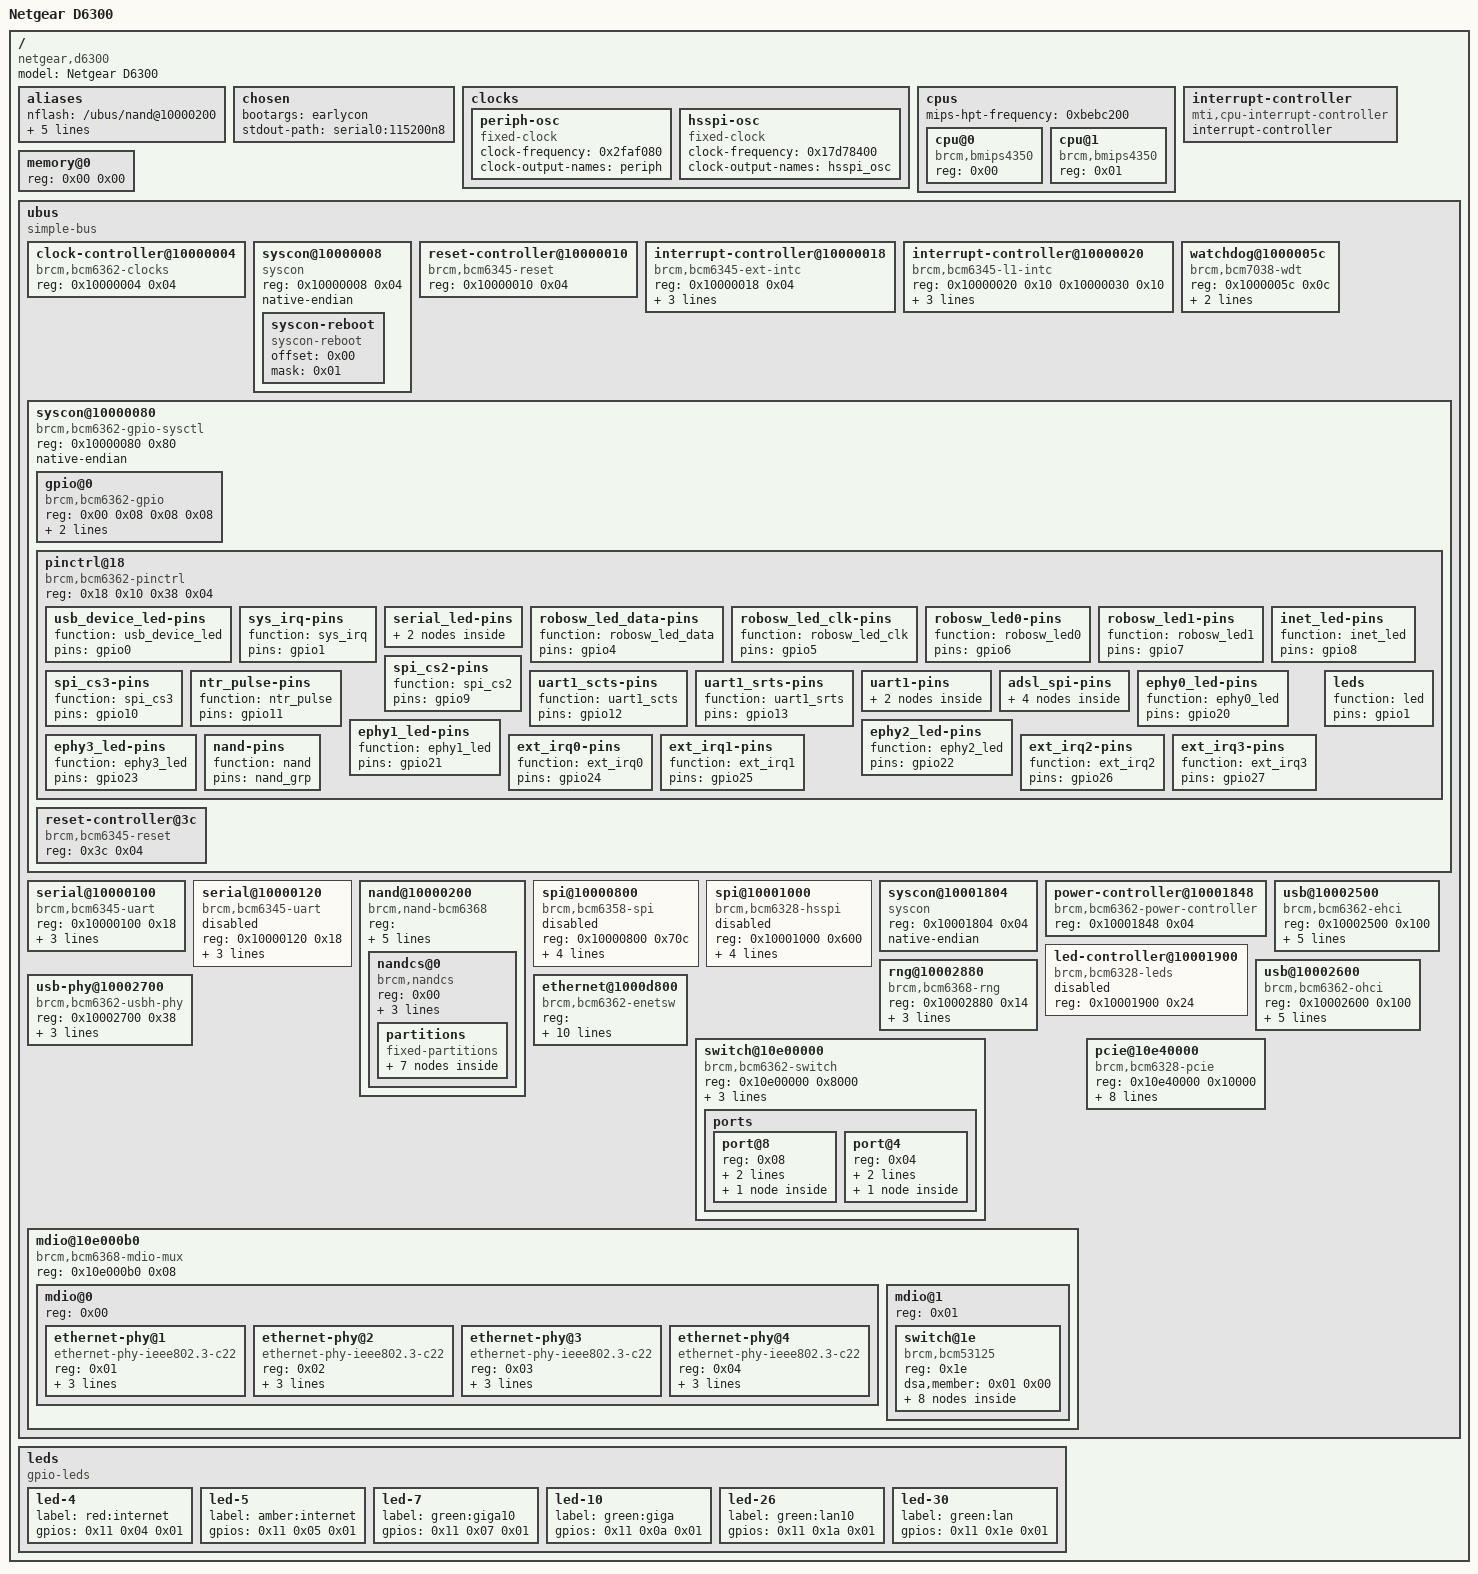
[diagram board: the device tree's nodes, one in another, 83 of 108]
/dts-v1/;

/ {
	#address-cells = <0x01>;
	#size-cells = <0x01>;
	compatible = "netgear,d6300", "brcm,bcm6362";
	model = "Netgear D6300";

	aliases {
		nflash = "/ubus/nand@10000200";
		pinctrl = "/ubus/syscon@10000080/pinctrl@18";
		serial0 = "/ubus/serial@10000100";
		serial1 = "/ubus/serial@10000120";
		spi0 = "/ubus/spi@10000800";
		spi1 = "/ubus/spi@10001000";
	};

	chosen {
		bootargs = "earlycon";
		stdout-path = "serial0:115200n8";
	};

	clocks {

		periph-osc {
			compatible = "fixed-clock";
			#clock-cells = <0x00>;
			clock-frequency = <0x2faf080>;
			clock-output-names = "periph";
			phandle = <0x03>;
		};

		hsspi-osc {
			compatible = "fixed-clock";
			#clock-cells = <0x00>;
			clock-frequency = <0x17d78400>;
			clock-output-names = "hsspi_osc";
			phandle = <0x08>;
		};
	};

	cpus {
		#address-cells = <0x01>;
		#size-cells = <0x00>;
		mips-hpt-frequency = <0xbebc200>;

		cpu@0 {
			compatible = "brcm,bmips4350", "mips,mips4Kc";
			device_type = "cpu";
			reg = <0x00>;
		};

		cpu@1 {
			compatible = "brcm,bmips4350", "mips,mips4Kc";
			device_type = "cpu";
			reg = <0x01>;
		};
	};

	interrupt-controller {
		#address-cells = <0x00>;
		compatible = "mti,cpu-interrupt-controller";
		interrupt-controller;
		#interrupt-cells = <0x01>;
		phandle = <0x02>;
	};

	memory@0 {
		device_type = "memory";
		reg = <0x00 0x00>;
	};

	ubus {
		#address-cells = <0x01>;
		#size-cells = <0x01>;
		compatible = "simple-bus";
		ranges;

		clock-controller@10000004 {
			compatible = "brcm,bcm6362-clocks";
			reg = <0x10000004 0x04>;
			#clock-cells = <0x01>;
			phandle = <0x05>;
		};

		syscon@10000008 {
			compatible = "syscon", "simple-mfd";
			reg = <0x10000008 0x04>;
			native-endian;

			syscon-reboot {
				compatible = "syscon-reboot";
				offset = <0x00>;
				mask = <0x01>;
			};
		};

		reset-controller@10000010 {
			compatible = "brcm,bcm6345-reset";
			reg = <0x10000010 0x04>;
			#reset-cells = <0x01>;
			phandle = <0x07>;
		};

		interrupt-controller@10000018 {
			#address-cells = <0x01>;
			compatible = "brcm,bcm6345-ext-intc";
			reg = <0x10000018 0x04>;
			interrupt-controller;
			#interrupt-cells = <0x02>;
			interrupt-parent = <0x01>;
			interrupts = <0x28 0x29 0x2a 0x2b>;
		};

		interrupt-controller@10000020 {
			#address-cells = <0x01>;
			compatible = "brcm,bcm6345-l1-intc";
			reg = <0x10000020 0x10 0x10000030 0x10>;
			interrupt-controller;
			#interrupt-cells = <0x01>;
			interrupt-parent = <0x02>;
			interrupts = <0x02 0x03>;
			phandle = <0x01>;
		};

		watchdog@1000005c {
			compatible = "brcm,bcm7038-wdt";
			reg = <0x1000005c 0x0c>;
			clocks = <0x03>;
			timeout-sec = <0x1e>;
		};

		syscon@10000080 {
			#address-cells = <0x01>;
			#size-cells = <0x01>;
			compatible = "brcm,bcm6362-gpio-sysctl", "syscon", "simple-mfd";
			reg = <0x10000080 0x80>;
			ranges = <0x00 0x10000080 0x80>;
			native-endian;
			phandle = <0x0c>;

			gpio@0 {
				compatible = "brcm,bcm6362-gpio";
				reg-names = "dirout", "dat";
				reg = <0x00 0x08 0x08 0x08>;
				gpio-controller;
				gpio-ranges = <0x04 0x00 0x00 0x30>;
				#gpio-cells = <0x02>;
				phandle = <0x11>;
			};

			pinctrl@18 {
				compatible = "brcm,bcm6362-pinctrl";
				reg = <0x18 0x10 0x38 0x04>;
				phandle = <0x04>;

				usb_device_led-pins {
					function = "usb_device_led";
					pins = "gpio0";
				};

				sys_irq-pins {
					function = "sys_irq";
					pins = "gpio1";
				};

				serial_led-pins {

					serial_led_clk-pins {
						function = "serial_led_clk";
						pins = "gpio2";
					};

					serial_led_data-pins {
						function = "serial_led_data";
						pins = "gpio3";
					};
				};

				robosw_led_data-pins {
					function = "robosw_led_data";
					pins = "gpio4";
				};

				robosw_led_clk-pins {
					function = "robosw_led_clk";
					pins = "gpio5";
				};

				robosw_led0-pins {
					function = "robosw_led0";
					pins = "gpio6";
				};

				robosw_led1-pins {
					function = "robosw_led1";
					pins = "gpio7";
				};

				inet_led-pins {
					function = "inet_led";
					pins = "gpio8";
				};

				spi_cs2-pins {
					function = "spi_cs2";
					pins = "gpio9";
				};

				spi_cs3-pins {
					function = "spi_cs3";
					pins = "gpio10";
				};

				ntr_pulse-pins {
					function = "ntr_pulse";
					pins = "gpio11";
				};

				uart1_scts-pins {
					function = "uart1_scts";
					pins = "gpio12";
				};

				uart1_srts-pins {
					function = "uart1_srts";
					pins = "gpio13";
				};

				uart1-pins {

					uart1_sdin-pins {
						function = "uart1_sdin";
						pins = "gpio14";
					};

					uart1_sdout-pins {
						function = "uart1_sdout";
						pins = "gpio15";
					};
				};

				adsl_spi-pins {

					adsl_spi_miso-pins {
						function = "adsl_spi_miso";
						pins = "gpio16";
					};

					adsl_spi_mosi-pins {
						function = "adsl_spi_mosi";
						pins = "gpio17";
					};

					adsl_spi_clk-pins {
						function = "adsl_spi_clk";
						pins = "gpio18";
					};

					adsl_spi_cs-pins {
						function = "adsl_spi_cs";
						pins = "gpio19";
					};
				};

				ephy0_led-pins {
					function = "ephy0_led";
					pins = "gpio20";
				};

				ephy1_led-pins {
					function = "ephy1_led";
					pins = "gpio21";
				};

				ephy2_led-pins {
					function = "ephy2_led";
					pins = "gpio22";
				};

				ephy3_led-pins {
					function = "ephy3_led";
					pins = "gpio23";
				};

				ext_irq0-pins {
					function = "ext_irq0";
					pins = "gpio24";
				};

				ext_irq1-pins {
					function = "ext_irq1";
					pins = "gpio25";
				};

				ext_irq2-pins {
					function = "ext_irq2";
					pins = "gpio26";
				};

				ext_irq3-pins {
					function = "ext_irq3";
					pins = "gpio27";
				};

				nand-pins {
					function = "nand";
					pins = "nand_grp";
					phandle = <0x06>;
				};

				leds {
					function = "led";
					pins = "gpio1";
				};
			};

			reset-controller@3c {
				compatible = "brcm,bcm6345-reset";
				reg = <0x3c 0x04>;
				#reset-cells = <0x01>;
				phandle = <0x0e>;
			};
		};

		serial@10000100 {
			compatible = "brcm,bcm6345-uart";
			reg = <0x10000100 0x18>;
			interrupt-parent = <0x01>;
			interrupts = <0x03>;
			clocks = <0x03>;
			clock-names = "periph";
			status = "okay";
		};

		serial@10000120 {
			compatible = "brcm,bcm6345-uart";
			reg = <0x10000120 0x18>;
			interrupt-parent = <0x01>;
			interrupts = <0x04>;
			clocks = <0x03>;
			clock-names = "periph";
			status = "disabled";
		};

		nand@10000200 {
			#address-cells = <0x01>;
			#size-cells = <0x00>;
			compatible = "brcm,nand-bcm6368", "brcm,brcmnand-v2.2", "brcm,brcmnand";
			reg = <0x10000200 0x180 0x10000600 0x200 0x10000070 0x10>;
			reg-names = "nand", "nand-cache", "nand-int-base";
			interrupt-parent = <0x01>;
			interrupts = <0x0c>;
			clocks = <0x05 0x14>;
			clock-names = "nand";
			pinctrl-names = "default";
			pinctrl-0 = <0x06>;
			status = "okay";

			nandcs@0 {
				compatible = "brcm,nandcs";
				reg = <0x00>;
				nand-ecc-step-size = <0x200>;
				nand-ecc-strength = <0x0f>;
				nand-on-flash-bbt;
				#address-cells = <0x01>;
				#size-cells = <0x01>;

				partitions {
					compatible = "fixed-partitions";
					#address-cells = <0x01>;
					#size-cells = <0x01>;

					partition@0 {
						label = "cferom";
						reg = <0x00 0x4000>;
						read-only;

						nvmem-layout {
							compatible = "fixed-layout";
							#address-cells = <0x01>;
							#size-cells = <0x01>;

							macaddr@6a0 {
								reg = <0x6a0 0x06>;
								phandle = <0x0b>;
							};
						};
					};

					partition@4000 {
						label = "rootfs_update";
						reg = <0x4000 0x1d7c000>;
					};

					partition@1d80000 {
						compatible = "brcm,wfi";
						label = "wfi";
						reg = <0x1d80000 0x1d7c000>;
						brcm,cferam = "cferam";
					};

					partition@3afc000 {
						label = "flag";
						reg = <0x3afc000 0x4000>;
						read-only;
					};

					partition@3b00000 {
						label = "data";
						reg = <0x3b00000 0x400000>;
					};
				};
			};
		};

		spi@10000800 {
			#address-cells = <0x01>;
			#size-cells = <0x00>;
			compatible = "brcm,bcm6358-spi";
			reg = <0x10000800 0x70c>;
			interrupt-parent = <0x01>;
			interrupts = <0x02>;
			clocks = <0x05 0x0f>;
			clock-names = "spi";
			resets = <0x07 0x00>;
			status = "disabled";
		};

		spi@10001000 {
			#address-cells = <0x01>;
			#size-cells = <0x00>;
			compatible = "brcm,bcm6328-hsspi";
			reg = <0x10001000 0x600>;
			interrupt-parent = <0x01>;
			interrupts = <0x05>;
			clocks = <0x05 0x10 0x08>;
			clock-names = "hsspi", "pll";
			resets = <0x07 0x00>;
			status = "disabled";
		};

		syscon@10001804 {
			compatible = "syscon";
			reg = <0x10001804 0x04>;
			native-endian;
			phandle = <0x10>;
		};

		power-controller@10001848 {
			compatible = "brcm,bcm6362-power-controller";
			reg = <0x10001848 0x04>;
			#power-domain-cells = <0x01>;
			phandle = <0x0a>;
		};

		led-controller@10001900 {
			#address-cells = <0x01>;
			#size-cells = <0x00>;
			compatible = "brcm,bcm6328-leds";
			reg = <0x10001900 0x24>;
			status = "disabled";
		};

		usb@10002500 {
			compatible = "brcm,bcm6362-ehci", "generic-ehci";
			reg = <0x10002500 0x100>;
			big-endian;
			spurious-oc;
			interrupt-parent = <0x01>;
			interrupts = <0x0a>;
			phys = <0x09 0x00>;
			phy-names = "usb";
			status = "okay";
		};

		usb@10002600 {
			compatible = "brcm,bcm6362-ohci", "generic-ohci";
			reg = <0x10002600 0x100>;
			big-endian;
			no-big-frame-no;
			interrupt-parent = <0x01>;
			interrupts = <0x09>;
			phys = <0x09 0x00>;
			phy-names = "usb";
			status = "okay";
		};

		usb-phy@10002700 {
			compatible = "brcm,bcm6362-usbh-phy";
			reg = <0x10002700 0x38>;
			#phy-cells = <0x01>;
			clocks = <0x05 0x0d>;
			clock-names = "usbh";
			power-domains = <0x0a 0x04>;
			resets = <0x07 0x06>;
			status = "okay";
			phandle = <0x09>;
		};

		rng@10002880 {
			compatible = "brcm,bcm6368-rng";
			reg = <0x10002880 0x14>;
			clocks = <0x05 0x0e>;
			clock-names = "ipsec";
			resets = <0x07 0x01>;
			power-domains = <0x0a 0x01>;
		};

		ethernet@1000d800 {
			compatible = "brcm,bcm6362-enetsw";
			reg = <0x1000d800 0x80 0x1000da00 0x80 0x1000dc00 0x80>;
			reg-names = "dma", "dma-channels", "dma-sram";
			interrupt-parent = <0x01>;
			interrupts = <0x20>;
			interrupt-names = "rx";
			clocks = <0x05 0x07 0x05 0x08 0x05 0x0a>;
			resets = <0x07 0x04 0x07 0x02>;
			power-domains = <0x0a 0x06 0x0a 0x0a>;
			dma-rx = <0x00>;
			dma-tx = <0x01>;
			status = "okay";
			nvmem-cells = <0x0b>;
			nvmem-cell-names = "mac-address";
			phandle = <0x0d>;
		};

		switch@10e00000 {
			#address-cells = <0x01>;
			#size-cells = <0x00>;
			compatible = "brcm,bcm6362-switch";
			reg = <0x10e00000 0x8000>;
			big-endian;
			brcm,gpio-ctrl = <0x0c>;
			dsa,member = <0x00 0x00>;

			ports {
				#address-cells = <0x01>;
				#size-cells = <0x00>;

				port@8 {
					reg = <0x08>;
					phy-mode = "internal";
					ethernet = <0x0d>;

					fixed-link {
						speed = <0x3e8>;
						full-duplex;
					};
				};

				port@4 {
					reg = <0x04>;
					label = "extsw";
					phy-mode = "rgmii-id";
					phandle = <0x0f>;

					fixed-link {
						speed = <0x3e8>;
						full-duplex;
					};
				};
			};
		};

		mdio@10e000b0 {
			#address-cells = <0x01>;
			#size-cells = <0x00>;
			compatible = "brcm,bcm6368-mdio-mux";
			reg = <0x10e000b0 0x08>;

			mdio@0 {
				#address-cells = <0x01>;
				#size-cells = <0x00>;
				reg = <0x00>;

				ethernet-phy@1 {
					compatible = "ethernet-phy-ieee802.3-c22";
					reg = <0x01>;
					resets = <0x0e 0x00>;
					reset-names = "phy";
					reset-assert-us = <0x7d0>;
					reset-deassert-us = <0x7d0>;
				};

				ethernet-phy@2 {
					compatible = "ethernet-phy-ieee802.3-c22";
					reg = <0x02>;
					resets = <0x0e 0x01>;
					reset-names = "phy";
					reset-assert-us = <0x7d0>;
					reset-deassert-us = <0x7d0>;
				};

				ethernet-phy@3 {
					compatible = "ethernet-phy-ieee802.3-c22";
					reg = <0x03>;
					resets = <0x0e 0x02>;
					reset-names = "phy";
					reset-assert-us = <0x7d0>;
					reset-deassert-us = <0x7d0>;
				};

				ethernet-phy@4 {
					compatible = "ethernet-phy-ieee802.3-c22";
					reg = <0x04>;
					resets = <0x0e 0x03>;
					reset-names = "phy";
					reset-assert-us = <0x7d0>;
					reset-deassert-us = <0x7d0>;
				};
			};

			mdio@1 {
				#address-cells = <0x01>;
				#size-cells = <0x00>;
				reg = <0x01>;

				switch@1e {
					compatible = "brcm,bcm53125";
					reg = <0x1e>;
					dsa,member = <0x01 0x00>;

					ports {
						#address-cells = <0x01>;
						#size-cells = <0x00>;

						port@0 {
							reg = <0x00>;
							label = "lan1";
						};

						port@1 {
							reg = <0x01>;
							label = "lan2";
						};

						port@2 {
							reg = <0x02>;
							label = "lan3";
						};

						port@3 {
							reg = <0x03>;
							label = "lan4";
						};

						port@4 {
							reg = <0x04>;
							label = "wan";
						};

						port@8 {
							reg = <0x08>;
							phy-mode = "rgmii-id";
							ethernet = <0x0f>;

							fixed-link {
								speed = <0x3e8>;
								full-duplex;
							};
						};
					};
				};
			};
		};

		pcie@10e40000 {
			compatible = "brcm,bcm6328-pcie";
			reg = <0x10e40000 0x10000>;
			#address-cells = <0x03>;
			#size-cells = <0x02>;
			device_type = "pci";
			bus-range = <0x00 0x01>;
			ranges = <0x2000000 0x00 0x10f00000 0x10f00000 0x00 0x100000>;
			linux,pci-probe-only = <0x01>;
			interrupt-parent = <0x01>;
			interrupts = <0x1e>;
			clocks = <0x05 0x11>;
			clock-names = "pcie";
			resets = <0x07 0x09 0x07 0x0a 0x07 0x08>;
			reset-names = "pcie", "pcie-ext", "pcie-core";
			power-domains = <0x0a 0x0c>;
			brcm,serdes = <0x10>;
			status = "okay";
		};
	};

	leds {
		compatible = "gpio-leds";

		led-4 {
			label = "red:internet";
			gpios = <0x11 0x04 0x01>;
		};

		led-5 {
			label = "amber:internet";
			gpios = <0x11 0x05 0x01>;
		};

		led-7 {
			label = "green:giga10";
			gpios = <0x11 0x07 0x01>;
		};

		led-10 {
			label = "green:giga";
			gpios = <0x11 0x0a 0x01>;
		};

		led-26 {
			label = "green:lan10";
			gpios = <0x11 0x1a 0x01>;
		};

		led-30 {
			label = "green:lan";
			gpios = <0x11 0x1e 0x01>;
		};
	};
};
